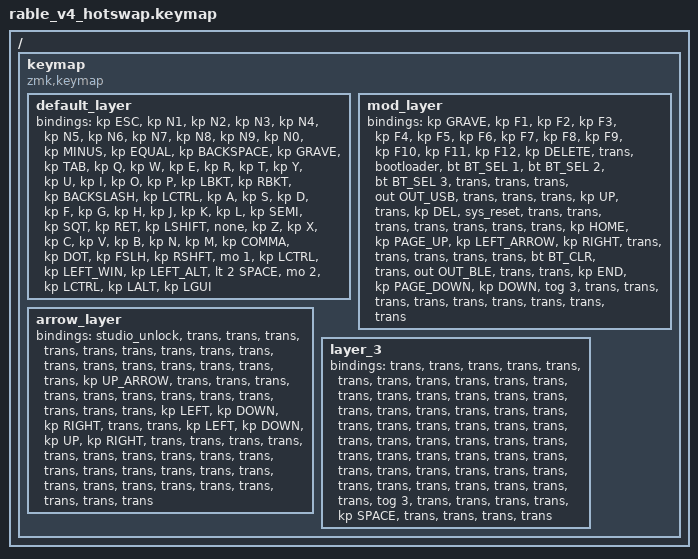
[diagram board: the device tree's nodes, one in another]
/*
 * Copyright (c) 2021 Nick Winans
 *
 * SPDX-License-Identifier: MIT
 */

#include <behaviors.dtsi>
#include <dt-bindings/zmk/bt.h>
#include <dt-bindings/zmk/keys.h>
#include <dt-bindings/zmk/outputs.h>

/ {
    keymap {
        compatible = "zmk,keymap";

        default_layer {
            bindings = <
&kp ESC  &kp N1  &kp N2  &kp N3  &kp N4  &kp N5  &kp N6  &kp N7  &kp N8  &kp N9  &kp N0  &kp MINUS  &kp EQUAL  &kp BACKSPACE  &kp GRAVE  &kp TAB  &kp Q  &kp W  &kp E  &kp R  &kp T  &kp Y  &kp U  &kp I  &kp O  &kp P  &kp LBKT  &kp RBKT  &kp BACKSLASH  &kp LCTRL  &kp A  &kp S  &kp D  &kp F  &kp G  &kp H  &kp J  &kp K  &kp L  &kp SEMI  &kp SQT  &kp RET  &kp LSHIFT  &none  &kp Z  &kp X  &kp C  &kp V  &kp B  &kp N  &kp M  &kp COMMA  &kp DOT  &kp FSLH  &kp RSHFT  &mo 1  &kp LCTRL  &kp LEFT_WIN  &kp LEFT_ALT  &lt 2 SPACE  &mo 2  &kp LCTRL  &kp LALT  &kp LGUI
            >;
        };

        mod_layer {
            // ----------------------------------------------------------------------------------------------------------------
            // |        |    | BT 1|BT 2 |BT 3 |BT 4 |     |     |     |     |     |     |     |     |BT CLR |         |
            // |        |    | RST | BOOT|     |     |     |     |     |     |     |     |     |     |       |         |
            // |        |    | USB | BLE |     |     |     |     |     |     |     |     |     |     |RGB TOG|         |
            // |        |    |EP_ON|EP_OFF|EP_TOG|     |     |     |     |     |     |     |     |     |       |         |
            // |        |    |     |     |                                               |     |     |       |         |
            // ----------------------------------------------------------------------------------------------------------------

            bindings = <
&kp GRAVE  &kp F1  &kp F2  &kp F3  &kp F4  &kp F5  &kp F6  &kp F7  &kp F8  &kp F9  &kp F10  &kp F11  &kp F12  &kp DELETE  &trans  &bootloader  &bt BT_SEL 1  &bt BT_SEL 2  &bt BT_SEL 3  &trans  &trans  &trans  &out OUT_USB  &trans  &trans  &trans  &kp UP  &trans  &kp DEL  &sys_reset  &trans  &trans  &trans  &trans  &trans  &trans  &trans  &kp HOME  &kp PAGE_UP  &kp LEFT_ARROW  &kp RIGHT  &trans  &trans  &trans  &trans  &trans  &bt BT_CLR  &trans  &out OUT_BLE  &trans  &trans  &kp END  &kp PAGE_DOWN  &kp DOWN  &tog 3  &trans  &trans  &trans  &trans  &trans  &trans  &trans  &trans  &trans
            >;
        };

        arrow_layer {
            // ----------------------------------------------------------------------------------------------------------------
            // |        |    |     |     |     |     |     |     |     |     |     |     |     |     |     |   `~    |
            // |        |    |     |     |     |     |     |     |     |     |     |     |     |     |     |         |
            // |        |    |     |     |     |     |     |LEFT |DOWN |  UP |RIGHT|     |     |     |     |         |
            // |        |    |     |     |     |     |     |     |     |     |     |     |     |     |     |         |
            // |        |    |     |     |                                               |     |     |     |         |
            // ----------------------------------------------------------------------------------------------------------------

            bindings = <
&studio_unlock  &trans  &trans  &trans  &trans  &trans  &trans  &trans  &trans  &trans  &trans  &trans  &trans  &trans  &trans  &trans  &trans  &kp UP_ARROW  &trans  &trans  &trans  &trans  &trans  &trans  &trans  &trans  &trans  &trans  &trans  &trans  &kp LEFT  &kp DOWN  &kp RIGHT  &trans  &trans  &kp LEFT  &kp DOWN  &kp UP  &kp RIGHT  &trans  &trans  &trans  &trans  &trans  &trans  &trans  &trans  &trans  &trans  &trans  &trans  &trans  &trans  &trans  &trans  &trans  &trans  &trans  &trans  &trans  &trans  &trans  &trans  &trans
            >;
        };

        layer_3 {
            bindings = <
&trans  &trans  &trans  &trans  &trans  &trans  &trans  &trans  &trans  &trans  &trans  &trans  &trans  &trans  &trans  &trans  &trans  &trans  &trans  &trans  &trans  &trans  &trans  &trans  &trans  &trans  &trans  &trans  &trans  &trans  &trans  &trans  &trans  &trans  &trans  &trans  &trans  &trans  &trans  &trans  &trans  &trans  &trans  &trans  &trans  &trans  &trans  &trans  &trans  &trans  &trans  &trans  &trans  &trans  &tog 3  &trans  &trans  &trans  &trans  &kp SPACE  &trans  &trans  &trans  &trans
            >;
        };
    };
};
